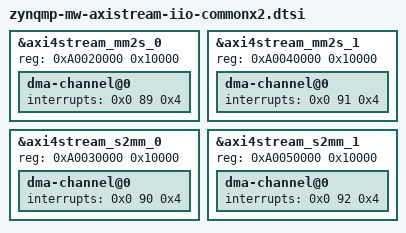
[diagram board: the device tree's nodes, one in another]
#include "zynqmp-mw-cma.dtsi"
#include "xilinx-mw-axistream-iio-commonx2.dtsi"

&axi4stream_mm2s_0 {
	reg = <0xA0020000 0x10000>;
	dma-channel@0  {
		interrupts = <0x0 89 0x4>;
	};
};

&axi4stream_mm2s_1 {
	reg = <0xA0040000 0x10000>;
	dma-channel@0  {
		interrupts = <0x0 91 0x4>;
	};
};

&axi4stream_s2mm_0 {
	reg = <0xA0030000 0x10000>;
	dma-channel@0  {
		interrupts = <0x0 90 0x4>;
	};
};

&axi4stream_s2mm_1 {
	reg = <0xA0050000 0x10000>;
	dma-channel@0  {
		interrupts = <0x0 92 0x4>;
	};
};

